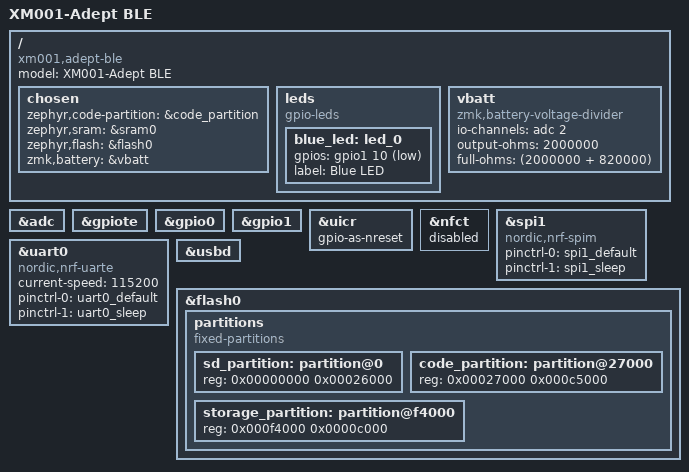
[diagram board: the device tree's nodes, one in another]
/*
 * XM001-Adept BLE board
 *
 * MCU module : EBYTE E73-2G4M08S1C  (nRF52833-QIAA aQFN73, 512 KB flash / 128 KB RAM)
 * Project    : XM001-Adept_BLE  (MIAOMIAO wuxian v1.3, PMW3610 trackball)
 *
 * Every GPIO was read out of ProDoc_sensor_3_2026-10-11.epro (PCB netlist) and
 * cross-checked against the Ebyte pin table plus two independent symbols.
 * See docs/pinmap.md.
 *
 * SPDX-License-Identifier: MIT
 */

/dts-v1/;
#include <nordic/nrf52833_qiaa.dtsi>
#include "xm001_adept_ble-pinctrl.dtsi"

/ {
	model = "XM001-Adept BLE";
	compatible = "xm001,adept-ble";

	chosen {
		zephyr,code-partition = &code_partition;
		zephyr,sram = &sram0;
		zephyr,flash = &flash0;
		zmk,battery = &vbatt;
	};

	leds {
		compatible = "gpio-leds";

		blue_led: led_0 {
			gpios = <&gpio1 10 GPIO_ACTIVE_LOW>;
			label = "Blue LED";
		};
	};

	/*
	 * NOTE: no VBUS-sense node here on purpose.  This board has no VBUS
	 * divider.  The only node that reacts to USB presence is AO3407 (Q1), a
	 * battery power-path switch whose gate sits on E73 pad 14 = P0.06, and
	 * the VBUS net reaches nothing but the E73 VBUS pin (pad 27) plus the
	 * charger and fuse.  P0.06 is therefore reserved.
	 */

	/* VBAT divider: R10 = 820K high side, R11 = 2M low side, on E73 pad 18
	 * (AI2 = AIN2 = P0.04). */
	vbatt: vbatt {
		compatible = "zmk,battery-voltage-divider";
		io-channels = <&adc 2>;
		output-ohms = <2000000>;
		full-ohms = <(2000000 + 820000)>;
	};
};

&adc {
	status = "okay";
};

&gpiote {
	status = "okay";
};

&gpio0 {
	status = "okay";
};

&gpio1 {
	status = "okay";
};

&uicr {
	gpio-as-nreset;
};

&nfct {
	status = "disabled";
};

&spi1 {
	compatible = "nordic,nrf-spim";
	pinctrl-0 = <&spi1_default>;
	pinctrl-1 = <&spi1_sleep>;
	pinctrl-names = "default", "sleep";
};

&uart0 {
	compatible = "nordic,nrf-uarte";
	current-speed = <115200>;
	pinctrl-0 = <&uart0_default>;
	pinctrl-1 = <&uart0_sleep>;
	pinctrl-names = "default", "sleep";
};

zephyr_udc0: &usbd {
	status = "okay";
};

&flash0 {
	/*
	 * Adafruit nRF52 UF2 bootloader layout, same offsets ZMK uses for
	 * nice_nano_v2: bootloader below 0x27000, application 0x27000, storage
	 * at the top of the 512 KB flash.
	 */
	partitions {
		compatible = "fixed-partitions";
		#address-cells = <1>;
		#size-cells = <1>;

		sd_partition: partition@0 {
			reg = <0x00000000 0x00026000>;
		};
		code_partition: partition@27000 {
			reg = <0x00027000 0x000c5000>;
		};

		/*
		 * 0x000EC000 .. 0x000F3FFF is reserved for the application.
		 */
		storage_partition: partition@f4000 {
			reg = <0x000f4000 0x0000c000>;
		};
	};
};
